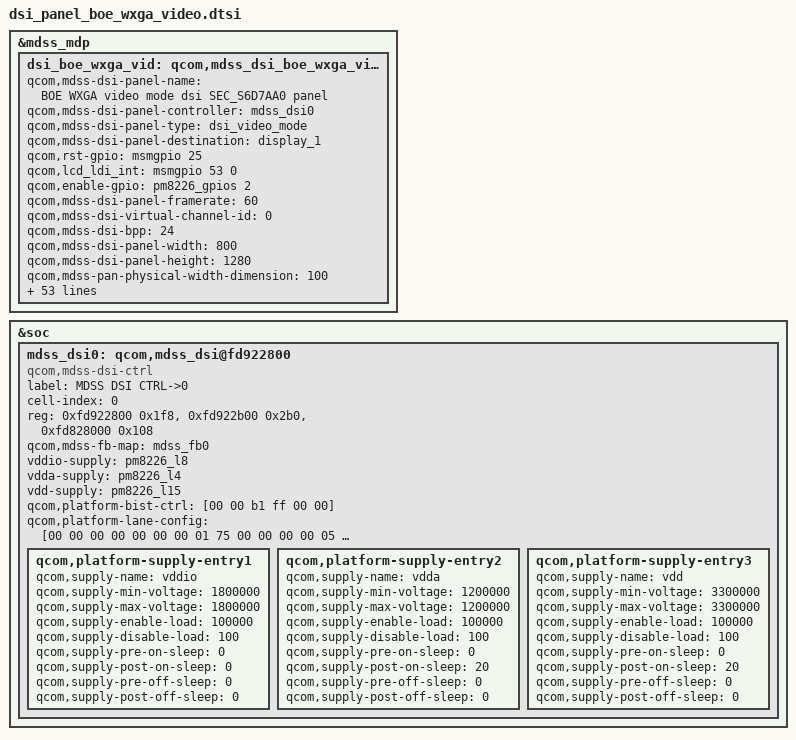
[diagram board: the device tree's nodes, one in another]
/* Copyright (c) 2013, The Linux Foundation. All rights reserved.
 *
 * This program is free software; you can redistribute it and/or modify
 * it under the terms of the GNU General Public License version 2 and
 * only version 2 as published by the Free Software Foundation.
 *
 * This program is distributed in the hope that it will be useful,
 * but WITHOUT ANY WARRANTY; without even the implied warranty of
 * MERCHANTABILITY or FITNESS FOR A PARTICULAR PURPOSE.  See the
 * GNU General Public License for more details.
 */

&mdss_mdp {
	dsi_boe_wxga_vid:qcom,mdss_dsi_boe_wxga_video {
		qcom,mdss-dsi-panel-name = "BOE WXGA video mode dsi SEC_S6D7AA0 panel";
		qcom,mdss-dsi-panel-controller = <&mdss_dsi0>;
		qcom,mdss-dsi-panel-type = "dsi_video_mode";
		qcom,mdss-dsi-panel-destination = "display_1";
		qcom,rst-gpio = <&msmgpio 25 0>;
		qcom,lcd_ldi_int = <&msmgpio 53 0>;
		qcom,enable-gpio = <&pm8226_gpios 2 0>;
		qcom,mdss-dsi-panel-framerate = <60>;
		qcom,mdss-dsi-virtual-channel-id = <0>;
		qcom,mdss-dsi-bpp = <24>;
		qcom,mdss-dsi-panel-width = <800>;
		qcom,mdss-dsi-panel-height = <1280>;
		qcom,mdss-pan-physical-width-dimension = <100>; /* <Width> real size of panel in mm */
		qcom,mdss-pan-physical-height-dimension = <161>; /*<Height> real size of panel in mm */
		qcom,mdss-dsi-lp11-init;
		qcom,mdss-dsi-init-delay-us = <100>;
		qcom,mdss-dsi-h-front-porch = <16>;
		qcom,mdss-dsi-h-back-porch = <48>;
		qcom,mdss-dsi-h-pulse-width = <16>;
		qcom,mdss-dsi-h-sync-skew = <0>;
		qcom,mdss-dsi-v-back-porch = <4>;
		qcom,mdss-dsi-v-front-porch = <8>;
		qcom,mdss-dsi-v-pulse-width = <4>;
		qcom,mdss-dsi-h-left-border = <0>;
		qcom,mdss-dsi-h-right-border = <0>;
		qcom,mdss-dsi-v-top-border = <0>;
		qcom,mdss-dsi-v-bottom-border = <0>;
		qcom,mdss-dsi-underflow-color = <0xff>;
		qcom,mdss-dsi-bl-pmic-control-type = "bl_ctrl_dcs";
		qcom,mdss-dsi-border-color = <0>;
		qcom,mdss-dsi-mdp-trigger = <0x0>;
		qcom,mdss-dsi-dma-trigger = <0x04>;
		qcom,mdss-dsi-bl-min-level = <1>;
		qcom,mdss-dsi-bl-max-level = <255>;
		qcom,mdss-dsi-color-order = <0>;
		qcom,mdss-pan-dsi-t-clk-pre = <0x26>;
		qcom,mdss-pan-dsi-t-clk-post = <0x04>;
		qcom,mdss-dsi-lane-0-state;
		qcom,mdss-dsi-lane-1-state;
		qcom,mdss-dsi-lane-2-state;
		qcom,mdss-dsi-lane-3-state;
		qcom,mdss-dsi-bllp-eof-power-mode;
		qcom,mdss-dsi-bllp-power-mode;
		qcom,mdss-dsi-traffic-mode = <0>;
		qcom,mdss-pan-dsi-dst-format = <3>;
		qcom,mdss-dsi-lane-map = <0>;
		qcom,mdss-dsi-h-sync-pulse = <0>;
		qcom,mdss-force-clk-lane-hs = <1>;
		qcom,mdss-dsi-stream = <0>;
		qcom,mdss-pan-dsi-mdp-tr = <0x0>;
		qcom,mdss-pan-dsi-dma-tr = <0x04>;
		qcom,mdss-dsi-panel-timings = [7B 1A 10 00 3E 40
						     16 1E 15 03 04 00];
		qcom,platform-strength-ctrl = [ff 06];
		qcom,platform-regulator-settings = [03 01 01 00 20 00 01];
		qcom,mdss-dsi-panel-clock-rate = <416000000>;
		qcom,mdss-dsi-on-command = [39 01 00 00 00 00 03 F0 5A 5A
					39 01 00 00 00 00 03 F1 5A 5A
					39 01 00 00 00 00 03 FC A5 A5
					39 01 00 00 01 00 03 D0 00 10
					39 01 00 00 00 00 04 C3 4D 01 28
					39 01 00 00 00 00 04 BC 00 4E A2
					39 01 00 00 00 00 05 FD 16 10 11 23
					39 01 00 00 00 00 07 FE 00 02 03 21 00 70
					39 01 00 00 00 00 02 53 26
					05 01 00 00 78 00 02 11 00      /* Sleep out */
					39 01 00 00 00 00 03 F0 A5 A5
					39 01 00 00 00 00 03 F1 A5 A5
					39 01 00 00 00 00 03 FC 5A 5A
					39 01 00 00 05 00 02 35 00
					05 01 00 00 00 00 02 29 00	/* Display On */
					];
		samsung,panel-manufacture-id-read-cmds = [06 01 00 00 00 00 01 da 01
							06 01 00 00 00 00 01 db 01
							06 01 00 00 00 00 01 dc 01];
		qcom,mdss-dsi-on-command-state = "dsi_lp_mode";
		qcom,mdss-dsi-off-command = [05 01 00 00 40 00 02 28 00
					39 01 00 00 01 00 03 F0 5A 5A
					39 01 00 00 01 00 04 C3 40 00 20
					05 01 00 00 0A 00 02 10 00
					];
		qcom,mdss-dsi-off-command-state = "dsi_hs_mode";
	};
};
&soc {
	mdss_dsi0: qcom,mdss_dsi@fd922800 {
		compatible = "qcom,mdss-dsi-ctrl";
		label = "MDSS DSI CTRL->0";
		cell-index = <0>;
		reg = 	<0xfd922800 0x1f8>,
			<0xfd922b00 0x2b0>,
			<0xfd828000 0x108>;
		reg-names = "dsi_ctrl", "dsi_phy", "mmss_misc_phys";
		qcom,mdss-fb-map = <&mdss_fb0>;
		vddio-supply = <&pm8226_l8>;
		vdda-supply = <&pm8226_l4>;
		vdd-supply = <&pm8226_l15>;
		qcom,platform-bist-ctrl = [00 00 b1 ff 00 00];
		qcom,platform-lane-config = [00 00 00 00 00 00 00 01 75
			00 00 00 00 05 00 00 01 75
			00 00 00 00 0a 00 00 01 75
			00 00 00 00 0f 00 00 01 75
			00 c0 00 00 00 00 00 01 97];
		qcom,platform-supply-entry1 {
			qcom,supply-name = "vddio";
			qcom,supply-min-voltage = <1800000>;
			qcom,supply-max-voltage = <1800000>;
			qcom,supply-enable-load = <100000>;
			qcom,supply-disable-load = <100>;
			qcom,supply-pre-on-sleep = <0>;
			qcom,supply-post-on-sleep = <0>;
			qcom,supply-pre-off-sleep = <0>;
			qcom,supply-post-off-sleep = <0>;
		};
		qcom,platform-supply-entry2 {
			qcom,supply-name = "vdda";
			qcom,supply-min-voltage = <1200000>;
			qcom,supply-max-voltage = <1200000>;
			qcom,supply-enable-load = <100000>;
			qcom,supply-disable-load = <100>;
			qcom,supply-pre-on-sleep = <0>;
			qcom,supply-post-on-sleep = <20>;
			qcom,supply-pre-off-sleep = <0>;
			qcom,supply-post-off-sleep = <0>;
		};
		qcom,platform-supply-entry3 {
			qcom,supply-name = "vdd";
			qcom,supply-min-voltage = <3300000>;
			qcom,supply-max-voltage = <3300000>;
			qcom,supply-enable-load = <100000>;
			qcom,supply-disable-load = <100>;
			qcom,supply-pre-on-sleep = <0>;
			qcom,supply-post-on-sleep = <20>;
			qcom,supply-pre-off-sleep = <0>;
			qcom,supply-post-off-sleep = <0>;
		};
	};
};
